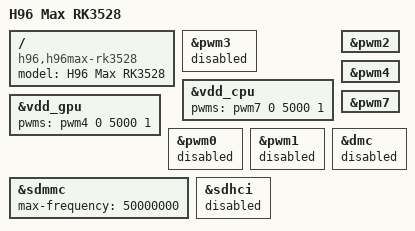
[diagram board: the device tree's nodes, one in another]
// SPDX-License-Identifier: (GPL-2.0+ OR MIT)
/dts-v1/;

#include "rk3528-hinlink-ht2.dts"

/ {
	model = "H96 Max RK3528";
	compatible = "h96,h96max-rk3528", "rockchip,rk3528";
};

&pwm3 { status = "disabled"; };

&vdd_cpu { pwms = <&pwm7 0 5000 1>; };
&vdd_gpu { pwms = <&pwm4 0 5000 1>; };

&pwm0 { status = "disabled"; };
&pwm1 { status = "disabled"; };
&pwm2 { status = "okay"; };
&pwm4 { status = "okay"; };
&pwm7 { status = "okay"; };

&sdmmc {
    max-frequency = <50000000>;

    /delete-property/ sd-uhs-sdr104;
    /delete-property/ sd-uhs-sdr50;
    /delete-property/ sd-uhs-sdr25;
    /delete-property/ sd-uhs-sdr12;
};

&dmc { status = "disabled"; };
&sdhci { status = "disabled"; };
